VERSION ""

NS_ :

BS_:

BU_: Node_A Node_B

BO_ 111 ID_frame_01: 8 Node_A
 SG_ SIG_ID01_01 : 7|8@0+ (1.0,0.0) [0|0] "" Receiver
 SG_ SIG_ID01_02 : 15|8@0+ (1.0,0.0) [0|0] "" Receiver
 SG_ SIG_ID01_03 : 23|8@0+ (1.0,0.0) [0|0] "" Receiver
 SG_ SIG_ID01_04 : 27|8@0+ (1.0,0.0) [0|0] "" Receiver
 SG_ SIG_ID01_05 : 31|8@0+ (1.0,0.0) [0|0] "" Receiver
 SG_ SIG_ID01_06 : 39|8@0+ (1.0,0.0) [0|0] "" Receiver
 SG_ SIG_ID01_07 : 47|8@0+ (1.0,0.0) [0|0] "" Receiver
 SG_ SIG_ID01_08 : 55|8@0+ (1.0,0.0) [0|0] "" Receiver

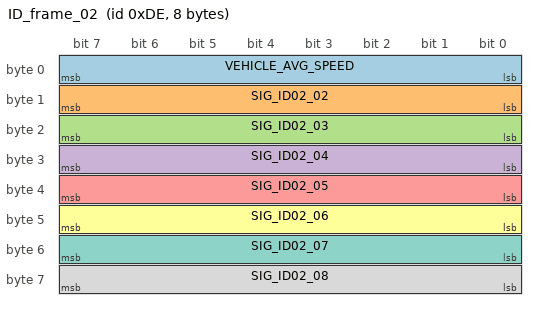
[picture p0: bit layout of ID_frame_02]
BO_ 222 ID_frame_02: 8 Node_B
 SG_ VEHICLE_AVG_SPEED : 0|8@1+ (1.0,0.0) [0|0] "" Receiver
 SG_ SIG_ID02_02 : 8|8@1+ (1.0,0.0) [0|0] "" Receiver
 SG_ SIG_ID02_03 : 16|8@1+ (1.0,0.0) [0|0] "" Receiver
 SG_ SIG_ID02_04 : 24|8@1+ (1.0,0.0) [0|0] "" Receiver
 SG_ SIG_ID02_05 : 32|8@1+ (1.0,0.0) [0|0] "" Receiver
 SG_ SIG_ID02_06 : 40|8@1+ (1.0,0.0) [0|0] "" Receiver
 SG_ SIG_ID02_07 : 48|8@1+ (1.0,0.0) [0|0] "" Receiver
 SG_ SIG_ID02_08 : 56|8@1+ (1.0,0.0) [0|0] "" Receiver
